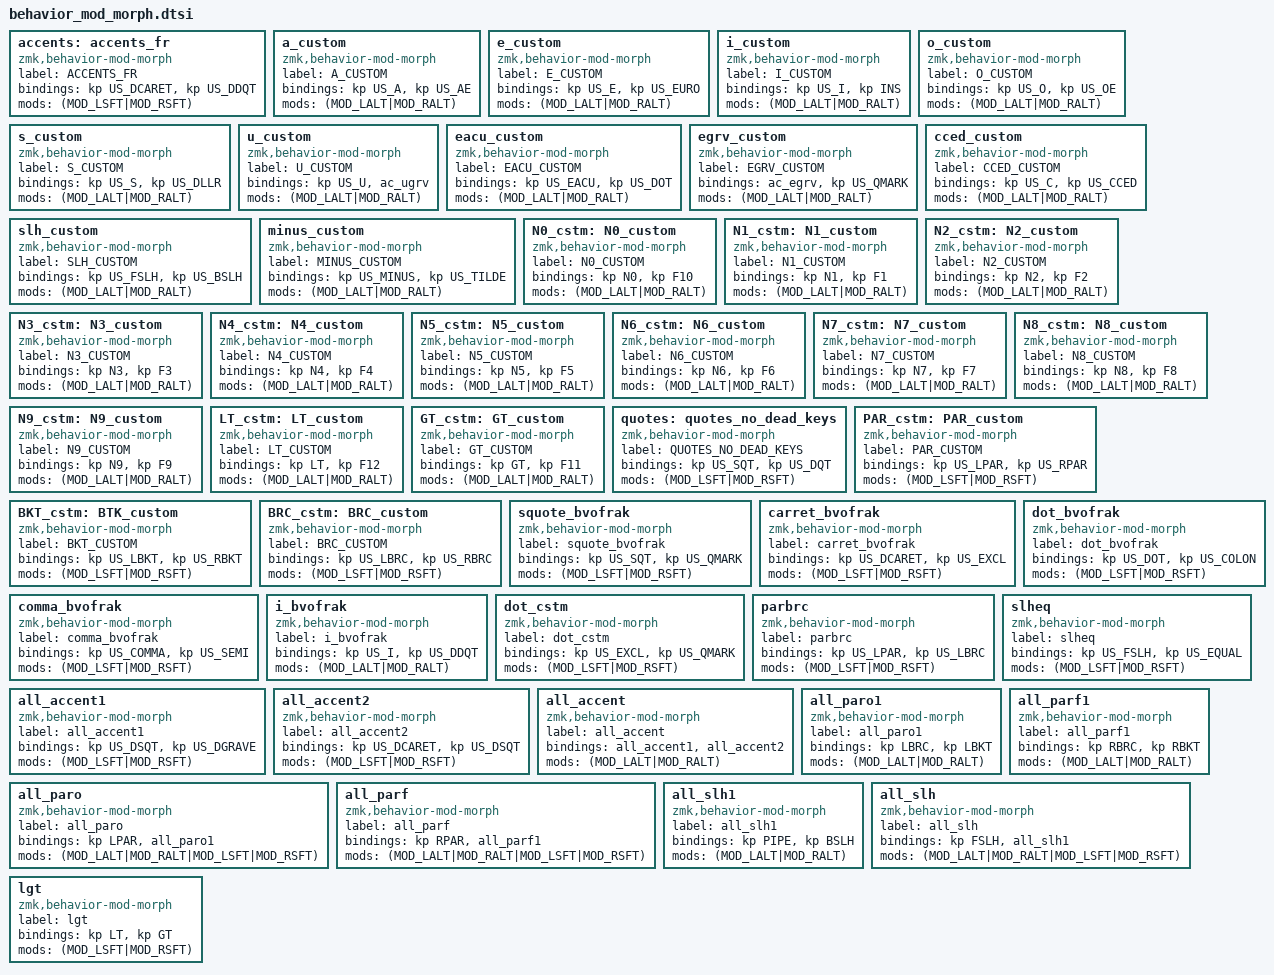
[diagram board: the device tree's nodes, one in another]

accents: accents_fr {
        compatible = "zmk,behavior-mod-morph";
        label = "ACCENTS_FR";
        #binding-cells = <0>;
        bindings = <&kp US_DCARET>, <&kp US_DDQT>;
        mods = <(MOD_LSFT|MOD_RSFT)>;
};
a_custom: a_custom {
        compatible = "zmk,behavior-mod-morph";
        label = "A_CUSTOM";
        #binding-cells = <0>;
        bindings = <&kp US_A>, <&kp US_AE>;
        mods = <(MOD_LALT|MOD_RALT)>;
};
e_custom: e_custom {
        compatible = "zmk,behavior-mod-morph";
        label = "E_CUSTOM";
        #binding-cells = <0>;
        bindings = <&kp US_E>, <&kp US_EURO>;
        mods = <(MOD_LALT|MOD_RALT)>;
};
i_custom: i_custom {
        compatible = "zmk,behavior-mod-morph";
        label = "I_CUSTOM";
        #binding-cells = <0>;
        bindings = <&kp US_I>, <&kp INS>;
        mods = <(MOD_LALT|MOD_RALT)>;
};
o_custom: o_custom {
        compatible = "zmk,behavior-mod-morph";
        label = "O_CUSTOM";
        #binding-cells = <0>;
        bindings = <&kp US_O>, <&kp US_OE>;
        mods = <(MOD_LALT|MOD_RALT)>;
};
s_custom: s_custom {
        compatible = "zmk,behavior-mod-morph";
        label = "S_CUSTOM";
        #binding-cells = <0>;
        bindings = <&kp US_S>, <&kp US_DLLR>;
        mods = <(MOD_LALT|MOD_RALT)>;
};
u_custom: u_custom {
        compatible = "zmk,behavior-mod-morph";
        label = "U_CUSTOM";
        #binding-cells = <0>;
        bindings = <&kp US_U>, <&ac_ugrv>;
        mods = <(MOD_LALT|MOD_RALT)>;
};
eacu_custom: eacu_custom {
        compatible = "zmk,behavior-mod-morph";
        label = "EACU_CUSTOM";
        #binding-cells = <0>;
        bindings = <&kp US_EACU>, <&kp US_DOT>;
        mods = <(MOD_LALT|MOD_RALT)>;
};
egrv_custom: egrv_custom {
        compatible = "zmk,behavior-mod-morph";
        label = "EGRV_CUSTOM";
        #binding-cells = <0>;
        bindings = <&ac_egrv>, <&kp US_QMARK>;
        mods = <(MOD_LALT|MOD_RALT)>;
};
cced_custom: cced_custom {
        compatible = "zmk,behavior-mod-morph";
        label = "CCED_CUSTOM";
        #binding-cells = <0>;
        bindings = <&kp US_C>, <&kp US_CCED>;
        mods = <(MOD_LALT|MOD_RALT)>;
};
slh_custom: slh_custom {
        compatible = "zmk,behavior-mod-morph";
        label = "SLH_CUSTOM";
        #binding-cells = <0>;
        bindings = <&kp US_FSLH>, <&kp US_BSLH>;
        mods = <(MOD_LALT|MOD_RALT)>;
};
minus_custom: minus_custom {
        compatible = "zmk,behavior-mod-morph";
        label = "MINUS_CUSTOM";
        #binding-cells = <0>;
        bindings = <&kp US_MINUS>, <&kp US_TILDE>;
        mods = <(MOD_LALT|MOD_RALT)>;
};
N0_cstm: N0_custom {
        compatible = "zmk,behavior-mod-morph";
        label = "N0_CUSTOM";
        #binding-cells = <0>;
        bindings = <&kp N0>, <&kp F10>;
        mods = <(MOD_LALT|MOD_RALT)>;
};
N1_cstm: N1_custom {
        compatible = "zmk,behavior-mod-morph";
        label = "N1_CUSTOM";
        #binding-cells = <0>;
        bindings = <&kp N1>, <&kp F1>;
        mods = <(MOD_LALT|MOD_RALT)>;
};
N2_cstm: N2_custom {
        compatible = "zmk,behavior-mod-morph";
        label = "N2_CUSTOM";
        #binding-cells = <0>;
        bindings = <&kp N2>, <&kp F2>;
        mods = <(MOD_LALT|MOD_RALT)>;
};
N3_cstm: N3_custom {
        compatible = "zmk,behavior-mod-morph";
        label = "N3_CUSTOM";
        #binding-cells = <0>;
        bindings = <&kp N3>, <&kp F3>;
        mods = <(MOD_LALT|MOD_RALT)>;
};
N4_cstm: N4_custom {
        compatible = "zmk,behavior-mod-morph";
        label = "N4_CUSTOM";
        #binding-cells = <0>;
        bindings = <&kp N4>, <&kp F4>;
        mods = <(MOD_LALT|MOD_RALT)>;
};
N5_cstm: N5_custom {
        compatible = "zmk,behavior-mod-morph";
        label = "N5_CUSTOM";
        #binding-cells = <0>;
        bindings = <&kp N5>, <&kp F5>;
        mods = <(MOD_LALT|MOD_RALT)>;
};
N6_cstm: N6_custom {
        compatible = "zmk,behavior-mod-morph";
        label = "N6_CUSTOM";
        #binding-cells = <0>;
        bindings = <&kp N6>, <&kp F6>;
        mods = <(MOD_LALT|MOD_RALT)>;
};
N7_cstm: N7_custom {
        compatible = "zmk,behavior-mod-morph";
        label = "N7_CUSTOM";
        #binding-cells = <0>;
        bindings = <&kp N7>, <&kp F7>;
        mods = <(MOD_LALT|MOD_RALT)>;
};
N8_cstm: N8_custom {
        compatible = "zmk,behavior-mod-morph";
        label = "N8_CUSTOM";
        #binding-cells = <0>;
        bindings = <&kp N8>, <&kp F8>;
        mods = <(MOD_LALT|MOD_RALT)>;
};
N9_cstm: N9_custom {
        compatible = "zmk,behavior-mod-morph";
        label = "N9_CUSTOM";
        #binding-cells = <0>;
        bindings = <&kp N9>, <&kp F9>;
        mods = <(MOD_LALT|MOD_RALT)>;
};
LT_cstm: LT_custom {
        compatible = "zmk,behavior-mod-morph";
        label = "LT_CUSTOM";
        #binding-cells = <0>;
        bindings = <&kp LT>, <&kp F12>;
        mods = <(MOD_LALT|MOD_RALT)>;
};
GT_cstm: GT_custom {
        compatible = "zmk,behavior-mod-morph";
        label = "GT_CUSTOM";
        #binding-cells = <0>;
        bindings = <&kp GT>, <&kp F11>;
        mods = <(MOD_LALT|MOD_RALT)>;
};
quotes: quotes_no_dead_keys {
        compatible = "zmk,behavior-mod-morph";
        label = "QUOTES_NO_DEAD_KEYS";
        #binding-cells = <0>;
        bindings = <&kp US_SQT>, <&kp US_DQT>;
        mods = <(MOD_LSFT|MOD_RSFT)>;
};
PAR_cstm: PAR_custom {
        compatible = "zmk,behavior-mod-morph";
        label = "PAR_CUSTOM";
        #binding-cells = <0>;
        bindings = <&kp US_LPAR>, <&kp US_RPAR>;
        mods = <(MOD_LSFT|MOD_RSFT)>;
};
BKT_cstm: BTK_custom {
        compatible = "zmk,behavior-mod-morph";
        label = "BKT_CUSTOM";
        #binding-cells = <0>;
        bindings = <&kp US_LBKT>, <&kp US_RBKT>;
        mods = <(MOD_LSFT|MOD_RSFT)>;
};
BRC_cstm: BRC_custom {
        compatible = "zmk,behavior-mod-morph";
        label = "BRC_CUSTOM";
        #binding-cells = <0>;
        bindings = <&kp US_LBRC>, <&kp US_RBRC>;
        mods = <(MOD_LSFT|MOD_RSFT)>;
};
squote_bvofrak: squote_bvofrak {
        compatible = "zmk,behavior-mod-morph";
        label = "squote_bvofrak";
        #binding-cells = <0>;
        bindings = <&kp US_SQT>, <&kp US_QMARK>;
        mods = <(MOD_LSFT|MOD_RSFT)>;
};
carret_bvofrak: carret_bvofrak {
        compatible = "zmk,behavior-mod-morph";
        label = "carret_bvofrak";
        #binding-cells = <0>;
        bindings = <&kp US_DCARET>, <&kp US_EXCL>;
        mods = <(MOD_LSFT|MOD_RSFT)>;
};
dot_bvofrak: dot_bvofrak {
        compatible = "zmk,behavior-mod-morph";
        label = "dot_bvofrak";
        #binding-cells = <0>;
        bindings = <&kp US_DOT>, <&kp US_COLON>;
        mods = <(MOD_LSFT|MOD_RSFT)>;
};
comma_bvofrak: comma_bvofrak {
        compatible = "zmk,behavior-mod-morph";
        label = "comma_bvofrak";
        #binding-cells = <0>;
        bindings = <&kp US_COMMA>, <&kp US_SEMI>;
        mods = <(MOD_LSFT|MOD_RSFT)>;
};
i_bvofrak: i_bvofrak {
        compatible = "zmk,behavior-mod-morph";
        label = "i_bvofrak";
        #binding-cells = <0>;
        bindings = <&kp US_I>, <&kp US_DDQT>;
        mods = <(MOD_LALT|MOD_RALT)>;
};
dot_cstm: dot_cstm {
        compatible = "zmk,behavior-mod-morph";
        label = "dot_cstm";
        #binding-cells = <0>;
        bindings = <&kp US_EXCL>, <&kp US_QMARK>;
        mods = <(MOD_LSFT|MOD_RSFT)>;
};
parbrc: parbrc {
        compatible = "zmk,behavior-mod-morph";
        label = "parbrc";
        #binding-cells = <0>;
        bindings = <&kp US_LPAR>, <&kp US_LBRC>;
        mods = <(MOD_LSFT|MOD_RSFT)>;
};
slheq: slheq {
        compatible = "zmk,behavior-mod-morph";
        label = "slheq";
        #binding-cells = <0>;
        bindings = <&kp US_FSLH>, <&kp US_EQUAL>;
        mods = <(MOD_LSFT|MOD_RSFT)>;
};
all_accent1: all_accent1 {
        compatible = "zmk,behavior-mod-morph";
        label = "all_accent1";
        #binding-cells = <0>;
        bindings = <&kp US_DSQT>, <&kp US_DGRAVE>;
        mods = <(MOD_LSFT|MOD_RSFT)>;
};
all_accent2: all_accent2 {
        compatible = "zmk,behavior-mod-morph";
        label = "all_accent2";
        #binding-cells = <0>;
        bindings = <&kp US_DCARET>, <&kp US_DSQT>;
        mods = <(MOD_LSFT|MOD_RSFT)>;
};
all_accent: all_accent {
        compatible = "zmk,behavior-mod-morph";
        label = "all_accent";
        #binding-cells = <0>;
        bindings = <&all_accent1>, <&all_accent2>;
        mods = <(MOD_LALT|MOD_RALT)>;
};
all_paro1: all_paro1 {
        compatible = "zmk,behavior-mod-morph";
        label = "all_paro1";
        #binding-cells = <0>;
        bindings = <&kp LBRC>, <&kp LBKT>;
        mods = <(MOD_LALT|MOD_RALT)>;
};
all_paro: all_paro {
        compatible = "zmk,behavior-mod-morph";
        label = "all_paro";
        #binding-cells = <0>;
        bindings = <&kp LPAR>, <&all_paro1>;
        mods = <(MOD_LALT|MOD_RALT|MOD_LSFT|MOD_RSFT)>;
};
all_parf1: all_parf1 {
        compatible = "zmk,behavior-mod-morph";
        label = "all_parf1";
        #binding-cells = <0>;
        bindings = <&kp RBRC>, <&kp RBKT>;
        mods = <(MOD_LALT|MOD_RALT)>;
};
all_parf: all_parf {
        compatible = "zmk,behavior-mod-morph";
        label = "all_parf";
        #binding-cells = <0>;
        bindings = <&kp RPAR>, <&all_parf1>;
        mods = <(MOD_LALT|MOD_RALT|MOD_LSFT|MOD_RSFT)>;
};
all_slh1: all_slh1 {
        compatible = "zmk,behavior-mod-morph";
        label = "all_slh1";
        #binding-cells = <0>;
        bindings = <&kp PIPE>, <&kp BSLH>;
        mods = <(MOD_LALT|MOD_RALT)>;
};
all_slh: all_slh {
        compatible = "zmk,behavior-mod-morph";
        label = "all_slh";
        #binding-cells = <0>;
        bindings = <&kp FSLH>, <&all_slh1>;
        mods = <(MOD_LALT|MOD_RALT|MOD_LSFT|MOD_RSFT)>;
};
lgt: lgt {
        compatible = "zmk,behavior-mod-morph";
        label = "lgt";
        #binding-cells = <0>;
        bindings = <&kp LT>, <&kp GT>;
        mods = <(MOD_LSFT|MOD_RSFT)>;
};
